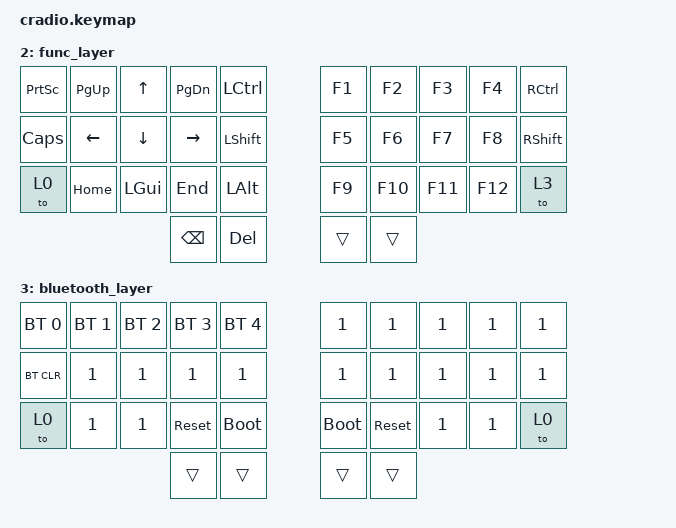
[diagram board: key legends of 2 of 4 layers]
// Copyright (c) 2022 The ZMK Contributors
// SPDX-License-Identifier: MIT

#include <behaviors.dtsi>
#include <dt-bindings/zmk/keys.h>
#include <dt-bindings/zmk/bt.h>

// Home row mods macro
#define HRML(k1,k2,k3,k4) &ht LGUI k1  &ht LALT k2  &ht LCTRL k3  &ht LSHFT k4
#define HRMR(k1,k2,k3,k4) &ht RSHFT k1  &ht RCTRL k2  &ht RALT k3  &ht RGUI k4

/ {
    behaviors {
        ht: hold_tap {
            compatible = "zmk,behavior-hold-tap";
            #binding-cells = <2>;
            flavor = "tap-preferred";
            tapping-term-ms = <500>;
            quick-tap-ms = <150>;
            require-prior-idle-ms = <200>;
            bindings = <&kp>, <&kp>;
        };
    };

    combos {
        compatible = "zmk,combos";
        combo_f2 {
            timeout-ms = <50>;
            key-positions = <1 2>;
            bindings = <&kp F2>;
        };
    };

    keymap {
        compatible = "zmk,keymap";
        default_layer {
            bindings = <
        //╭──────────┬──────────┬──────────┬──────────┬──────────╮   ╭──────────┬──────────┬──────────┬──────────┬──────────╮
        //│  Q       │  W       │  E       │  R       │  T       │   │  Y       │  U       │  I       │  O       │  P       │
            &kp Q      &kp W      &kp E      &kp R      &kp T          &kp Y      &kp U      &kp I      &kp O      &kp P
        //├──────────┼──────────┼──────────┼──────────┼──────────┤   ├──────────┼──────────┼──────────┼──────────┼──────────┤
        //│  A       │  S       │  D       │  F       │  G       │   │  H       │  J       │  K       │  L       │ ' "      │
            HRML(A,        S,         D,         F)     &kp G          &kp H      HRMR(J,        K,         L,        SQT)
        //├──────────┼──────────┼──────────┼──────────┼──────────┤   ├──────────┼──────────┼──────────┼──────────┼──────────┤
        //│  Z       │  X       │  C       │  V       │  B       │   │  N       │  M       │ , <      │ . >      │ TO 1     │
            &kp Z      &kp X      &kp C      &kp V      &kp B          &kp N      &kp M      &kp COMMA  &kp DOT    &to 1
        //╰──────────┴──────────┴──────────┼──────────┼──────────┤   ├──────────┼──────────┼──────────┴──────────┴──────────╯
                                             &kp BSPC   &kp DEL        &kp ENTER  &kp SPACE
        //                                 ╰──────────┴──────────╯   ╰──────────┴──────────╯
            >;
        };

        number_layer {
            bindings = <
        //╭──────────┬──────────┬──────────┬──────────┬──────────╮   ╭──────────┬──────────┬──────────┬──────────┬──────────╮
        //│ ESC      │  7       │  8       │  9       │  /       │   │          │          │          │ /        │  \       │
            &kp ESC    &kp N7     &kp N8     &kp N9     &kp FSLH       &trans     &trans     &trans     &kp FSLH    &kp BSLH
        //├──────────┼──────────┼──────────┼──────────┼──────────┤   ├──────────┼──────────┼──────────┼──────────┼──────────┤
        //│ TAB      │  4       │  5       │  6       │          │   |  BSPC    │ [        │ ]        │ `        │   ;      │
            HRML(TAB,     N4,       N5,        N6)      &kp MINUS      &kp BSPC  HRMR(LBKT,   RBKT,      GRAVE,     SEMI)
        //├──────────┼──────────┼──────────┼──────────┼──────────┤   ├──────────┼──────────┼──────────┼──────────┼──────────┤
        //│ TO 0     │  1       │  2       │  3       │  =   +   │   │  DEL     │  BSPC    │  DEL     │          │  TO 2    │
            &to 0       &kp N1     &kp N2     &kp N3    &kp EQUAL      &kp DEL    &kp BSPC   &kp DEL     &trans     &to 2
        //╰──────────┴──────────┴──────────┼──────────┼──────────┤   ├──────────┼──────────┼──────────┴──────────┴──────────╯
                                             &kp N0      &kp DOT        &trans     &trans
        //                                 ╰──────────┴──────────╯   ╰──────────┴──────────╯
            >;
        };

        func_layer {
            bindings = <
        //╭──────────┬──────────┬──────────┬──────────┬──────────╮   ╭──────────┬──────────┬──────────┬──────────┬──────────╮
        //│  PRNTSC  │  PG_UP   │  UP      │  PG_DN   │  CTRL    │   │  F1      │  F2      │  F3      │  F4      │  CTRL    │
            &kp PSCRN  &kp PG_UP   &kp UP   &kp PG_DN   &kp LCTRL      &kp F1     &kp F2     &kp F3     &kp F4     &kp RCTRL
        //├──────────┼──────────┼──────────┼──────────┼──────────┤   ├──────────┼──────────┼──────────┼──────────┼──────────┤
        //│  CAPS    │  LEFT    │  DOWN    │  RIGHT   │  SHIFT   │   │  F5      │  F6      │  F7      │  F8      │  SHIFT   │
            &kp CAPS   &kp LEFT   &kp DOWN   &kp RIGHT  &kp LSHFT      &kp F5     &kp F6     &kp F7     &kp F8     &kp RSHFT
        //├──────────┼──────────┼──────────┼──────────┼──────────┤   ├──────────┼──────────┼──────────┼──────────┼──────────┤
        //│  TO 0    │  HOME    │   GUI    │  END     │  ALT     │   │  F9      │  F10     │  F11     │  F12     │ TO 3     │
            &to 0      &kp HOME   &kp LGUI   &kp END    &kp LALT       &kp F9     &kp F10    &kp F11    &kp F12    &to 3
        //╰──────────┴──────────┴──────────┼──────────┼──────────┤   ├──────────┼──────────┼──────────┴──────────┴──────────╯
                                             &kp BSPC   &kp DEL         &trans     &trans
        //                                 ╰──────────┴──────────╯   ╰──────────┴──────────╯
            >;
        };

        bluetooth_layer {
            bindings = <
        //╭──────────┬──────────┬──────────┬──────────┬──────────╮   ╭──────────┬──────────┬──────────┬──────────┬──────────╮
        //│ PROFILE 0│ PROFILE 1│ PROFILE 2│ PROFILE 3| PROFILE 4│   │          │          │          │          │          │
 &bt BT_SEL 0  &bt BT_SEL 1  &bt BT_SEL 2  &bt BT_SEL 3  &bt BT_SEL 4   &kp N1     &kp N1     &kp N1     &kp N1     &kp N1
        //├──────────┼──────────┼──────────┼──────────┼──────────┤   ├──────────┼──────────┼──────────┼──────────┼──────────┤
        //│ CLEAR BT │          │          │          |          │   │          │          │          │          │          │
           &bt BT_CLR   &kp N1     &kp N1     &kp N1    &kp N1          &kp N1     &kp N1     &kp N1     &kp N1     &kp N1
        //├──────────┼──────────┼──────────┼──────────┼──────────┤   ├──────────┼──────────┼──────────┼──────────┼──────────┤
        //│ TO 0     │          │          │  RESET   │BOOTLOADER│   │BOOTLOADER│  RESET   │          │          │ TO 0     │
            &to 0      &kp N1     &kp N1    &sys_reset &bootloader    &bootloader &sys_reset  &kp N1     &kp N1     &to 0
        //╰──────────┴──────────┴──────────┼──────────┼──────────┤   ├──────────┼──────────┼──────────┴──────────┴──────────╯
                                             &trans     &trans         &trans     &trans
        //                                 ╰──────────┴──────────╯   ╰──────────┴──────────╯
            >;
        };
    };
};
